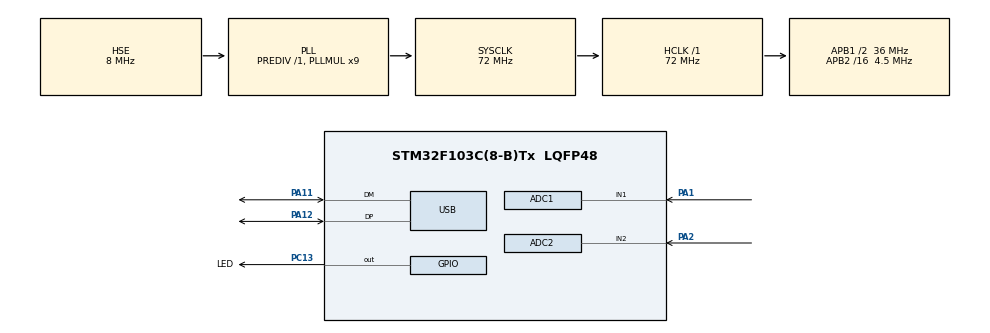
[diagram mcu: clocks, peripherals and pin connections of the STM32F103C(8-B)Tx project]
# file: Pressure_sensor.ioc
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ADC1.Channel-4\#ChannelRegularConversion=ADC_CHANNEL_1
ADC1.ContinuousConvMode=ENABLE
ADC1.DataAlign=ADC_DATAALIGN_RIGHT
ADC1.EnableAnalogWatchDog=false
ADC1.EnableInjectedConversion=DISABLE
ADC1.EnableRegularConversion=ENABLE
ADC1.Mode=ADC_DUALMODE_REGSIMULT
ADC1.NbrOfConversion=1
ADC1.NbrOfConversionFlag=1
ADC1.Rank-4\#ChannelRegularConversion=1
ADC1.SamplingTime-4\#ChannelRegularConversion=ADC_SAMPLETIME_239CYCLES_5
ADC1.master=1
ADC2.Channel-3\#ChannelRegularConversion=ADC_CHANNEL_2
ADC2.ContinuousConvMode=ENABLE
ADC2.EnableRegularConversion=ENABLE
ADC2.Mode=ADC_DUALMODE_REGSIMULT
ADC2.NbrOfConversionFlag=1
ADC2.Rank-3\#ChannelRegularConversion=1
ADC2.SamplingTime-3\#ChannelRegularConversion=ADC_SAMPLETIME_239CYCLES_5
Dma.ADC1.0.Direction=DMA_PERIPH_TO_MEMORY
Dma.ADC1.0.Instance=DMA1_Channel1
Dma.ADC1.0.MemDataAlignment=DMA_MDATAALIGN_WORD
Dma.ADC1.0.MemInc=DMA_MINC_ENABLE
Dma.ADC1.0.Mode=DMA_CIRCULAR
Dma.ADC1.0.PeriphDataAlignment=DMA_PDATAALIGN_WORD
Dma.ADC1.0.PeriphInc=DMA_PINC_DISABLE
Dma.ADC1.0.Priority=DMA_PRIORITY_LOW
Dma.Request0=ADC1
FREERTOS.Tasks01=defaultTask,0,128,StartDefaultTask,Default,NULL,Dynamic,NULL,NULL
Mcu.Family=STM32F1
Mcu.Name=STM32F103C(8-B)Tx
Mcu.Package=LQFP48
NVIC.DMA1_Channel1_IRQn=true\:5\:0\:false\:false\:true\:true\:false\:true
NVIC.PriorityGroup=NVIC_PRIORITYGROUP_4
NVIC.TIM1_UP_IRQn=true\:15\:0\:false\:false\:true\:false\:false\:true
NVIC.TimeBase=TIM1_UP_IRQn
NVIC.TimeBaseIP=TIM1
NVIC.USB_LP_CAN1_RX0_IRQn=true\:5\:0\:false\:false\:true\:true\:false\:true
PA1.Signal=ADCx_IN1
PA11.Mode=Device
PA11.Signal=USB_DM
PA12.Mode=Device
PA12.Signal=USB_DP
PA13.Mode=Serial_Wire
PA13.Signal=SYS_JTMS-SWDIO
PA14.Mode=Serial_Wire
PA14.Signal=SYS_JTCK-SWCLK
PA2.Signal=ADCx_IN2
PC13-TAMPER-RTC.GPIO_Label=LED
PC13-TAMPER-RTC.Signal=GPIO_Output
PD0-OSC_IN.Mode=HSE-External-Oscillator
PD0-OSC_IN.Signal=RCC_OSC_IN
PD1-OSC_OUT.Mode=HSE-External-Oscillator
PD1-OSC_OUT.Signal=RCC_OSC_OUT
ProjectManager.HeapSize=0x200
ProjectManager.StackSize=0x400
ProjectManager.TargetToolchain=STM32CubeIDE
RCC.ADCPresc=RCC_ADCPCLK2_DIV8
RCC.AHBFreq_Value=72000000
RCC.APB1CLKDivider=RCC_HCLK_DIV2
RCC.APB1Freq_Value=36000000
RCC.APB1TimFreq_Value=72000000
RCC.APB2CLKDivider=RCC_HCLK_DIV16
RCC.APB2Freq_Value=4500000
RCC.APB2TimFreq_Value=9000000
RCC.HCLKFreq_Value=72000000
RCC.PLLMUL=RCC_PLL_MUL9
RCC.PLLSourceVirtual=RCC_PLLSOURCE_HSE
RCC.SYSCLKFreq_VALUE=72000000
RCC.SYSCLKSource=RCC_SYSCLKSOURCE_PLLCLK
RCC.USBFreq_Value=48000000
RCC.USBPrescaler=RCC_USBCLKSOURCE_PLL_DIV1_5
SH.ADCx_IN1.0=ADC1_IN1,IN1
SH.ADCx_IN2.0=ADC2_IN2,IN2
USB_DEVICE.CLASS_NAME_FS=CDC
USB_DEVICE.VirtualMode=Cdc
USB_DEVICE.VirtualModeFS=Cdc_FS
VP_FREERTOS_VS_CMSIS_V1.Mode=CMSIS_V1
VP_SYS_VS_tim1.Mode=TIM1
VP_USB_DEVICE_VS_USB_DEVICE_CDC_FS.Mode=CDC_FS
board=custom

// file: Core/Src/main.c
/* USER CODE BEGIN Header */
/**
  ******************************************************************************
  * @file           : main.c
  * @brief          : Main program body
  ******************************************************************************
  * @attention
  *
  * Copyright (c) 2022 STMicroelectronics.
  * All rights reserved.
  *
  * This software is licensed under terms that can be found in the LICENSE file
  * in the root directory of this software component.
  * If no LICENSE file comes with this software, it is provided AS-IS.
  *
  ******************************************************************************
  */
/* USER CODE END Header */
#include "main.h"
#include "cmsis_os.h"
#include "adc.h"
#include "dma.h"
#include "usb_device.h"
#include "gpio.h"

/* USER CODE BEGIN Includes */
#include "usbd_cdc_if.h"
/* USER CODE END Includes */

/* USER CODE BEGIN PD */
#define ADC_BUFFER_SIZE 256
#define ADC_HALF_BUFFER_SIZE_IN_BYTES 2*ADC_BUFFER_SIZE
/* USER CODE END PD */

/* USER CODE BEGIN PV */
uint32_t adc_buf[ADC_BUFFER_SIZE];
/* USER CODE END PV */

void SystemClock_Config(void);
void MX_FREERTOS_Init(void);

int main(void)
{

  /* MCU Configuration--------------------------------------------------------*/

  /* Reset of all peripherals, Initializes the Flash interface and the Systick. */
  HAL_Init();

  /* Configure the system clock */
  SystemClock_Config();

  /* Initialize all configured peripherals */
  MX_GPIO_Init();
  MX_DMA_Init();
  MX_ADC1_Init();
  MX_ADC2_Init();
  /* USER CODE BEGIN 2 */
  HAL_ADC_Start(&hadc2);
  HAL_ADCEx_MultiModeStart_DMA(&hadc1, adc_buf, ADC_BUFFER_SIZE);
  /* USER CODE END 2 */

  /* Call init function for freertos objects (in freertos.c) */
  MX_FREERTOS_Init();
  /* Start scheduler */
  osKernelStart();

  /* We should never get here as control is now taken by the scheduler */
  /* Infinite loop */
  while (1)
  {

  }
}

void SystemClock_Config(void)
{
  RCC_OscInitTypeDef RCC_OscInitStruct = {0};
  RCC_ClkInitTypeDef RCC_ClkInitStruct = {0};
  RCC_PeriphCLKInitTypeDef PeriphClkInit = {0};

  /** Initializes the RCC Oscillators according to the specified parameters
  * in the RCC_OscInitTypeDef structure.
  */
  RCC_OscInitStruct.OscillatorType = RCC_OSCILLATORTYPE_HSE;
  RCC_OscInitStruct.HSEState = RCC_HSE_ON;
  RCC_OscInitStruct.HSEPredivValue = RCC_HSE_PREDIV_DIV1;
  RCC_OscInitStruct.HSIState = RCC_HSI_ON;
  RCC_OscInitStruct.PLL.PLLState = RCC_PLL_ON;
  RCC_OscInitStruct.PLL.PLLSource = RCC_PLLSOURCE_HSE;
  RCC_OscInitStruct.PLL.PLLMUL = RCC_PLL_MUL9;
  if (HAL_RCC_OscConfig(&RCC_OscInitStruct) != HAL_OK)
  {
    Error_Handler();
  }
  /** Initializes the CPU, AHB and APB buses clocks
  */
  RCC_ClkInitStruct.ClockType = RCC_CLOCKTYPE_HCLK|RCC_CLOCKTYPE_SYSCLK
                              |RCC_CLOCKTYPE_PCLK1|RCC_CLOCKTYPE_PCLK2;
  RCC_ClkInitStruct.SYSCLKSource = RCC_SYSCLKSOURCE_PLLCLK;
  RCC_ClkInitStruct.AHBCLKDivider = RCC_SYSCLK_DIV1;
  RCC_ClkInitStruct.APB1CLKDivider = RCC_HCLK_DIV2;
  RCC_ClkInitStruct.APB2CLKDivider = RCC_HCLK_DIV16;

  if (HAL_RCC_ClockConfig(&RCC_ClkInitStruct, FLASH_LATENCY_2) != HAL_OK)
  {
    Error_Handler();
  }
  PeriphClkInit.PeriphClockSelection = RCC_PERIPHCLK_ADC|RCC_PERIPHCLK_USB;
  PeriphClkInit.AdcClockSelection = RCC_ADCPCLK2_DIV8;
  PeriphClkInit.UsbClockSelection = RCC_USBCLKSOURCE_PLL_DIV1_5;
  if (HAL_RCCEx_PeriphCLKConfig(&PeriphClkInit) != HAL_OK)
  {
    Error_Handler();
  }
}

/* USER CODE BEGIN 4 */
void HAL_ADC_ConvHalfCpltCallback(ADC_HandleTypeDef *hadc){
	CDC_Transmit_FS((uint8_t*)adc_buf, ADC_HALF_BUFFER_SIZE_IN_BYTES);
}

void HAL_ADC_ConvCpltCallback(ADC_HandleTypeDef *hadc){
	CDC_Transmit_FS((uint8_t*)adc_buf + ADC_HALF_BUFFER_SIZE_IN_BYTES, ADC_HALF_BUFFER_SIZE_IN_BYTES);
}

/* USER CODE END 4 */

void HAL_TIM_PeriodElapsedCallback(TIM_HandleTypeDef *htim)
{
  if (htim->Instance == TIM1) {
    HAL_IncTick();
  }
}

void Error_Handler(void)
{
  __disable_irq();
  while (1)
  {
  }
}
